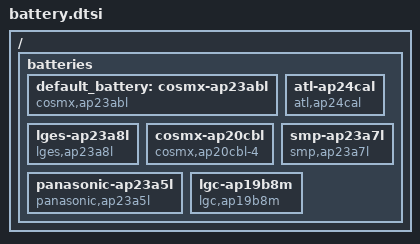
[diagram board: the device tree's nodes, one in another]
/* Copyright 2024 The ChromiumOS Authors
 * Use of this source code is governed by a BSD-style license that can be
 * found in the LICENSE file.
 */

/ {
	batteries {
		default_battery: cosmx-ap23abl {
			compatible = "cosmx,ap23abl", "battery-smart";
		};
		atl-ap24cal {
			compatible = "atl,ap24cal", "battery-smart";
		};
		lges-ap23a8l {
			compatible = "lges,ap23a8l", "battery-smart";
		};
		cosmx-ap20cbl {
			compatible = "cosmx,ap20cbl-4", "battery-smart";
		};
		panasonic-ap23a5l {
			compatible = "panasonic,ap23a5l", "battery-smart";
		};
		smp-ap23a7l {
			compatible = "smp,ap23a7l", "battery-smart";
		};
		lgc-ap19b8m {
			compatible = "lgc,ap19b8m", "battery-smart";
		};
	};
};
